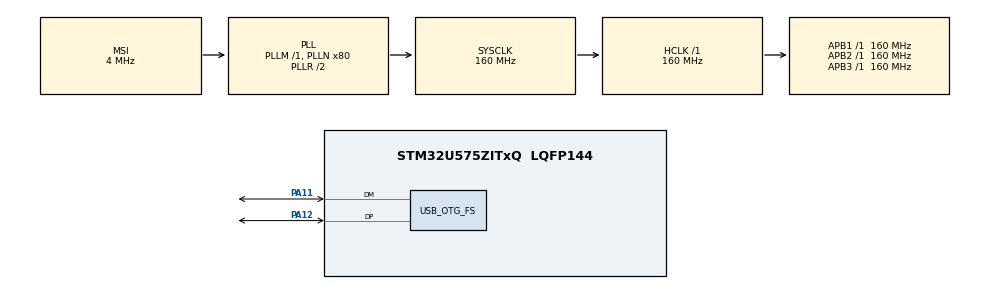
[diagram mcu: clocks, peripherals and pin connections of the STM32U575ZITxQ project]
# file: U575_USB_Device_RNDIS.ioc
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CORTEX_M33_NS.userName=CORTEX_M33
Mcu.Family=STM32U5
Mcu.Name=STM32U575ZITxQ
Mcu.Package=LQFP144
NVIC.OTG_FS_IRQn=true\:0\:0\:false\:false\:true\:true\:true\:true
NVIC.PriorityGroup=NVIC_PRIORITYGROUP_4
PA11.Mode=Device_Only
PA11.Signal=USB_OTG_FS_DM
PA12.Mode=Device_Only
PA12.Signal=USB_OTG_FS_DP
ProjectManager.HeapSize=0x2000
ProjectManager.StackSize=0x400
ProjectManager.TargetToolchain=STM32CubeIDE
RCC.ADCFreq_Value=16000000
RCC.AHBFreq_Value=160000000
RCC.APB1Freq_Value=160000000
RCC.APB1TimFreq_Value=160000000
RCC.APB2Freq_Value=160000000
RCC.APB2TimFreq_Value=160000000
RCC.APB3Freq_Value=160000000
RCC.CortexFreq_Value=160000000
RCC.EPOD_VALUE=4000000
RCC.HCLKFreq_Value=160000000
RCC.HSE_VALUE=16000000
RCC.HSI48_VALUE=48000000
RCC.HSI_VALUE=16000000
RCC.LSE_VALUE=32768
RCC.LSIDIV_VALUE=32000
RCC.MSI_VALUE=4000000
RCC.PLLN=80
RCC.SYSCLKFreq_VALUE=160000000
RCC.SYSCLKSource=RCC_SYSCLKSOURCE_PLLCLK
RCC.USBFreq_Value=48000000
RCC.VCOOutputFreq_Value=320000000
USB_OTG_FS.VirtualMode=Device_Only
VP_ICACHE_VS_ICACHE.Mode=DirectMappedCache
VP_LPBAMQUEUE_VS_QUEUE.Mode=QUEUEMODE
VP_LPBAM_VS_SIG1.Mode=SmartRun
VP_LPBAM_VS_SIG4.Mode=LPDMA1
VP_MEMORYMAP_VS_MEMORYMAP.Mode=CurAppReg
VP_PWR_VS_SECSignals.Mode=Security/Privilege
VP_RCC_USB.Mode=CRS SYNC Source USB
board=custom

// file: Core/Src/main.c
/* USER CODE BEGIN Header */
/**
  ******************************************************************************
  * @file           : main.c
  * @brief          : Main program body
  ******************************************************************************
  * @attention
  *
  * Copyright (c) 2024 STMicroelectronics.
  * All rights reserved.
  *
  * This software is licensed under terms that can be found in the LICENSE file
  * in the root directory of this software component.
  * If no LICENSE file comes with this software, it is provided AS-IS.
  *
  ******************************************************************************
  */
/* USER CODE END Header */
#include "main.h"

/* USER CODE BEGIN Includes */
#include "usb_device.h"
/* USER CODE END Includes */

PCD_HandleTypeDef hpcd_USB_OTG_FS;

/* USER CODE BEGIN PV */
USBD_HandleTypeDef        USBD_Device;
struct netif              gnetif;
__IO uint32_t LEDTimer =  LED_TIMER_LONG;
/* USER CODE END PV */

void SystemClock_Config(void);
static void MX_GPIO_Init(void);
static void MX_USB_OTG_FS_PCD_Init(void);
static void MX_ICACHE_Init(void);

int main(void)
{

  /* MCU Configuration--------------------------------------------------------*/

  /* Reset of all peripherals, Initializes the Flash interface and the Systick. */
  HAL_Init();

  /* Configure the system clock */
  SystemClock_Config();

  /* Initialize all configured peripherals */
  MX_GPIO_Init();
  // MX_USB_OTG_FS_PCD_Init();
  MX_ICACHE_Init();
  /* USER CODE BEGIN 2 */
  /* Initialize all configured peripherals */
  MX_USB_Device_Init();
  /* USER CODE END 2 */

  /* Infinite loop */
  while (1)
  {

    /* USER CODE BEGIN 3 */
        /* Background process of CDC_RNDIS class */
    USBD_CDC_RNDIS_fops.Process(&USBD_Device);
  }
  /* USER CODE END 3 */
}

void SystemClock_Config(void)
{
  RCC_OscInitTypeDef RCC_OscInitStruct = {0};
  RCC_ClkInitTypeDef RCC_ClkInitStruct = {0};
  RCC_CRSInitTypeDef RCC_CRSInitStruct = {0};

  /** Configure the main internal regulator output voltage
  */
  if (HAL_PWREx_ControlVoltageScaling(PWR_REGULATOR_VOLTAGE_SCALE1) != HAL_OK)
  {
    Error_Handler();
  }

  /** Initializes the CPU, AHB and APB buses clocks
  */
  RCC_OscInitStruct.OscillatorType = RCC_OSCILLATORTYPE_HSI48|RCC_OSCILLATORTYPE_MSI;
  RCC_OscInitStruct.HSI48State = RCC_HSI48_ON;
  RCC_OscInitStruct.MSIState = RCC_MSI_ON;
  RCC_OscInitStruct.MSICalibrationValue = RCC_MSICALIBRATION_DEFAULT;
  RCC_OscInitStruct.MSIClockRange = RCC_MSIRANGE_4;
  RCC_OscInitStruct.PLL.PLLState = RCC_PLL_ON;
  RCC_OscInitStruct.PLL.PLLSource = RCC_PLLSOURCE_MSI;
  RCC_OscInitStruct.PLL.PLLMBOOST = RCC_PLLMBOOST_DIV1;
  RCC_OscInitStruct.PLL.PLLM = 1;
  RCC_OscInitStruct.PLL.PLLN = 80;
  RCC_OscInitStruct.PLL.PLLP = 2;
  RCC_OscInitStruct.PLL.PLLQ = 2;
  RCC_OscInitStruct.PLL.PLLR = 2;
  RCC_OscInitStruct.PLL.PLLRGE = RCC_PLLVCIRANGE_0;
  RCC_OscInitStruct.PLL.PLLFRACN = 0;
  if (HAL_RCC_OscConfig(&RCC_OscInitStruct) != HAL_OK)
  {
    Error_Handler();
  }

  /** Initializes the CPU, AHB and APB buses clocks
  */
  RCC_ClkInitStruct.ClockType = RCC_CLOCKTYPE_HCLK|RCC_CLOCKTYPE_SYSCLK
                              |RCC_CLOCKTYPE_PCLK1|RCC_CLOCKTYPE_PCLK2
                              |RCC_CLOCKTYPE_PCLK3;
  RCC_ClkInitStruct.SYSCLKSource = RCC_SYSCLKSOURCE_PLLCLK;
  RCC_ClkInitStruct.AHBCLKDivider = RCC_SYSCLK_DIV1;
  RCC_ClkInitStruct.APB1CLKDivider = RCC_HCLK_DIV1;
  RCC_ClkInitStruct.APB2CLKDivider = RCC_HCLK_DIV1;
  RCC_ClkInitStruct.APB3CLKDivider = RCC_HCLK_DIV1;

  if (HAL_RCC_ClockConfig(&RCC_ClkInitStruct, FLASH_LATENCY_4) != HAL_OK)
  {
    Error_Handler();
  }

  /** Enable the SYSCFG APB clock
  */
  __HAL_RCC_CRS_CLK_ENABLE();

  /** Configures CRS
  */
  RCC_CRSInitStruct.Prescaler = RCC_CRS_SYNC_DIV1;
  RCC_CRSInitStruct.Source = RCC_CRS_SYNC_SOURCE_USB;
  RCC_CRSInitStruct.Polarity = RCC_CRS_SYNC_POLARITY_RISING;
  RCC_CRSInitStruct.ReloadValue = __HAL_RCC_CRS_RELOADVALUE_CALCULATE(48000000,1000);
  RCC_CRSInitStruct.ErrorLimitValue = 34;
  RCC_CRSInitStruct.HSI48CalibrationValue = 32;

  HAL_RCCEx_CRSConfig(&RCC_CRSInitStruct);
}

static void MX_ICACHE_Init(void)
{

  /** Enable instruction cache in 1-way (direct mapped cache)
  */
  if (HAL_ICACHE_ConfigAssociativityMode(ICACHE_1WAY) != HAL_OK)
  {
    Error_Handler();
  }
  if (HAL_ICACHE_Enable() != HAL_OK)
  {
    Error_Handler();
  }

}

static void MX_USB_OTG_FS_PCD_Init(void)
{

  hpcd_USB_OTG_FS.Instance = USB_OTG_FS;
  hpcd_USB_OTG_FS.Init.dev_endpoints = 6;
  hpcd_USB_OTG_FS.Init.speed = PCD_SPEED_FULL;
  hpcd_USB_OTG_FS.Init.phy_itface = PCD_PHY_EMBEDDED;
  hpcd_USB_OTG_FS.Init.Sof_enable = DISABLE;
  hpcd_USB_OTG_FS.Init.low_power_enable = DISABLE;
  hpcd_USB_OTG_FS.Init.lpm_enable = DISABLE;
  hpcd_USB_OTG_FS.Init.battery_charging_enable = DISABLE;
  hpcd_USB_OTG_FS.Init.use_dedicated_ep1 = DISABLE;
  hpcd_USB_OTG_FS.Init.vbus_sensing_enable = DISABLE;
  hpcd_USB_OTG_FS.Init.dma_enable = DISABLE;
  if (HAL_PCD_Init(&hpcd_USB_OTG_FS) != HAL_OK)
  {
    Error_Handler();
  }

}

static void MX_GPIO_Init(void)
{

  /* GPIO Ports Clock Enable */
  __HAL_RCC_GPIOA_CLK_ENABLE();

}

void Error_Handler(void)
{
  __disable_irq();
  while (1)
  {
  }
}
